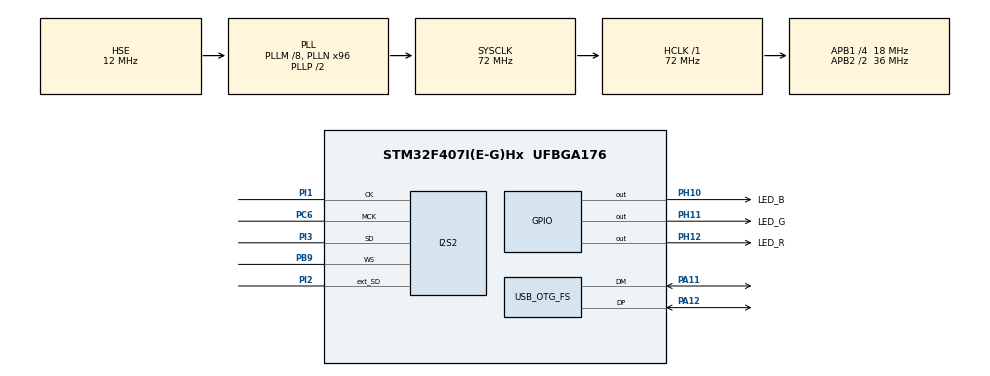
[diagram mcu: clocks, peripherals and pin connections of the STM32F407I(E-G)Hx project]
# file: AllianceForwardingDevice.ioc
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Dma.Request0=SPI2_TX
Dma.SPI2_TX.0.Direction=DMA_MEMORY_TO_PERIPH
Dma.SPI2_TX.0.FIFOMode=DMA_FIFOMODE_ENABLE
Dma.SPI2_TX.0.FIFOThreshold=DMA_FIFO_THRESHOLD_FULL
Dma.SPI2_TX.0.Instance=DMA1_Stream4
Dma.SPI2_TX.0.MemBurst=DMA_MBURST_INC8
Dma.SPI2_TX.0.MemDataAlignment=DMA_MDATAALIGN_HALFWORD
Dma.SPI2_TX.0.MemInc=DMA_MINC_ENABLE
Dma.SPI2_TX.0.Mode=DMA_CIRCULAR
Dma.SPI2_TX.0.PeriphBurst=DMA_PBURST_INC8
Dma.SPI2_TX.0.PeriphDataAlignment=DMA_PDATAALIGN_HALFWORD
Dma.SPI2_TX.0.PeriphInc=DMA_PINC_DISABLE
Dma.SPI2_TX.0.Priority=DMA_PRIORITY_LOW
I2S2.AudioFreq=I2S_AUDIOFREQ_48K
I2S2.ErrorAudioFreq=-0.08 %
I2S2.FullDuplexMode=I2S_FULLDUPLEXMODE_ENABLE
I2S2.Instance=SPI$Index
I2S2.RealAudioFreq=47.96 KHz
I2S2.VirtualMode=I2S_MODE_MASTER
Mcu.Family=STM32F4
Mcu.Name=STM32F407I(E-G)Hx
Mcu.Package=UFBGA176
NVIC.DMA1_Stream4_IRQn=true\:0\:0\:false\:false\:true\:false\:true\:true
NVIC.OTG_FS_IRQn=true\:0\:0\:false\:false\:true\:false\:true\:true
NVIC.PriorityGroup=NVIC_PRIORITYGROUP_4
PA11.Mode=Device_Only
PA11.Signal=USB_OTG_FS_DM
PA12.Mode=Device_Only
PA12.Signal=USB_OTG_FS_DP
PA13.Mode=Serial_Wire
PA13.Signal=SYS_JTMS-SWDIO
PA14.Mode=Serial_Wire
PA14.Signal=SYS_JTCK-SWCLK
PB9.Mode=Full_Duplex_Master
PB9.Signal=I2S2_WS
PC6.Mode=Master_Clock_Activated
PC6.Signal=I2S2_MCK
PH0-OSC_IN.Mode=HSE-External-Oscillator
PH0-OSC_IN.Signal=RCC_OSC_IN
PH1-OSC_OUT.Mode=HSE-External-Oscillator
PH1-OSC_OUT.Signal=RCC_OSC_OUT
PH10.GPIO_Label=LED_B
PH10.Signal=GPIO_Output
PH11.GPIO_Label=LED_G
PH11.Signal=GPIO_Output
PH12.GPIO_Label=LED_R
PH12.Signal=GPIO_Output
PI1.Mode=Full_Duplex_Master
PI1.Signal=I2S2_CK
PI2.Mode=Full_Duplex_Master
PI2.Signal=I2S2_ext_SD
PI3.Mode=Full_Duplex_Master
PI3.Signal=I2S2_SD
ProjectManager.HeapSize=0x4000
ProjectManager.StackSize=0x2000
ProjectManager.TargetToolchain=STM32CubeIDE
RCC.48MHZClocksFreq_Value=48000000
RCC.AHBFreq_Value=72000000
RCC.APB1CLKDivider=RCC_HCLK_DIV4
RCC.APB1Freq_Value=18000000
RCC.APB1TimFreq_Value=36000000
RCC.APB2CLKDivider=RCC_HCLK_DIV2
RCC.APB2Freq_Value=36000000
RCC.APB2TimFreq_Value=72000000
RCC.CortexFreq_Value=72000000
RCC.HCLKFreq_Value=72000000
RCC.HSE_VALUE=12000000
RCC.HSI_VALUE=16000000
RCC.LSE_VALUE=32768
RCC.PLLI2SN=221
RCC.PLLI2SR=3
RCC.PLLM=8
RCC.PLLN=96
RCC.PLLQ=3
RCC.SYSCLKFreq_VALUE=72000000
RCC.SYSCLKSource=RCC_SYSCLKSOURCE_PLLCLK
RCC.VCOOutputFreq_Value=144000000
USB_DEVICE.CLASS_NAME_FS=AUDIO
USB_DEVICE.USBD_AUDIO_FREQ-AUDIO_FS=0xbb80
USB_DEVICE.USBD_MAX_NUM_INTERFACES-AUDIO_FS=2
USB_DEVICE.VirtualMode-AUDIO_FS=Audio
USB_DEVICE.VirtualModeFS=Audio_FS
USB_OTG_FS.VirtualMode=Device_Only
VP_USB_DEVICE_VS_USB_DEVICE_AUDIO_FS.Mode=AUDIO_FS
board=custom

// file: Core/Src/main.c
/* USER CODE BEGIN Header */
/**
 ******************************************************************************
 * @file           : main.c
 * @brief          : Main program body
 ******************************************************************************
 * @attention
 *
 * Copyright (c) 2024 STMicroelectronics.
 * All rights reserved.
 *
 * This software is licensed under terms that can be found in the LICENSE file
 * in the root directory of this software component.
 * If no LICENSE file comes with this software, it is provided AS-IS.
 *
 ******************************************************************************
 */
/* USER CODE END Header */
#include "main.h"
#include "dma.h"
#include "i2s.h"
#include "usb_device.h"
#include "gpio.h"

/* USER CODE BEGIN Includes */
#include "usbd_audio_if.h"
/* USER CODE END Includes */

void SystemClock_Config(void);

int main(void)
{

  /* USER CODE BEGIN 1 */
  unsigned char recv_buffer[0x1e0];
  unsigned char send_buffer[0x1e0] = "Alliance Forwarding Device";
  int len = 88;
  /* USER CODE END 1 */

  /* MCU Configuration--------------------------------------------------------*/

  /* Reset of all peripherals, Initializes the Flash interface and the Systick. */
  HAL_Init();

  /* Configure the system clock */
  SystemClock_Config();

  /* Initialize all configured peripherals */
  MX_GPIO_Init();
  MX_DMA_Init();
  MX_I2S2_Init();
  MX_USB_DEVICE_Init();
  HAL_Delay(1000);
  /* USER CODE BEGIN 2 */
  // len = 0;
  int k = 0;
  /* USER CODE END 2 */

  /* Infinite loop */
  /* USER CODE BEGIN WHILE */
  while (1)
  {
    char buf[10];
    __itoa(k++, buf, 10);
    strcpy(send_buffer + strlen("Alliance Forwarding Device"), buf);
    USBD_AUDIO_fops_FS.Receive(recv_buffer, &len);
    USBD_AUDIO_fops_FS.Transmit(send_buffer, 0x1e0);
    HAL_Delay(1);
    // USBD_Interface_fops_FS.Receive(buffer, &len);

    /* USER CODE END WHILE */

  }
}

void SystemClock_Config(void)
{
  RCC_OscInitTypeDef RCC_OscInitStruct = {0};
  RCC_ClkInitTypeDef RCC_ClkInitStruct = {0};

  /** Configure the main internal regulator output voltage
   */
  __HAL_RCC_PWR_CLK_ENABLE();
  __HAL_PWR_VOLTAGESCALING_CONFIG(PWR_REGULATOR_VOLTAGE_SCALE1);

  /** Initializes the RCC Oscillators according to the specified parameters
   * in the RCC_OscInitTypeDef structure.
   */
  RCC_OscInitStruct.OscillatorType = RCC_OSCILLATORTYPE_HSE;
  RCC_OscInitStruct.HSEState = RCC_HSE_ON;
  RCC_OscInitStruct.PLL.PLLState = RCC_PLL_ON;
  RCC_OscInitStruct.PLL.PLLSource = RCC_PLLSOURCE_HSE;
  RCC_OscInitStruct.PLL.PLLM = 8;
  RCC_OscInitStruct.PLL.PLLN = 96;
  RCC_OscInitStruct.PLL.PLLP = RCC_PLLP_DIV2;
  RCC_OscInitStruct.PLL.PLLQ = 3;
  if (HAL_RCC_OscConfig(&RCC_OscInitStruct) != HAL_OK)
  {
    Error_Handler();
  }

  /** Initializes the CPU, AHB and APB buses clocks
   */
  RCC_ClkInitStruct.ClockType = RCC_CLOCKTYPE_HCLK | RCC_CLOCKTYPE_SYSCLK | RCC_CLOCKTYPE_PCLK1 | RCC_CLOCKTYPE_PCLK2;
  RCC_ClkInitStruct.SYSCLKSource = RCC_SYSCLKSOURCE_PLLCLK;
  RCC_ClkInitStruct.AHBCLKDivider = RCC_SYSCLK_DIV1;
  RCC_ClkInitStruct.APB1CLKDivider = RCC_HCLK_DIV4;
  RCC_ClkInitStruct.APB2CLKDivider = RCC_HCLK_DIV2;

  if (HAL_RCC_ClockConfig(&RCC_ClkInitStruct, FLASH_LATENCY_2) != HAL_OK)
  {
    Error_Handler();
  }
}

void Error_Handler(void)
{
  __disable_irq();
  while (1)
  {
  }
}
